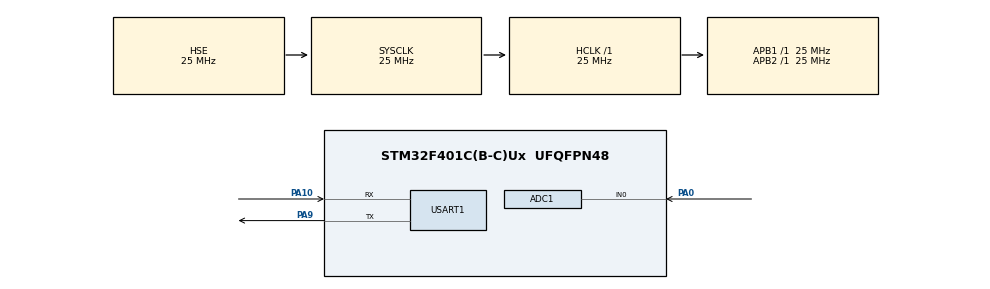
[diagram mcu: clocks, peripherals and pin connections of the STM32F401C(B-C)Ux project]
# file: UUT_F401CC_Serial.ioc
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Mcu.Family=STM32F4
Dma.ADC1.0.Instance=DMA2_Stream0
RCC.CortexFreq_Value=25000000
ADC1.Rank-0\#ChannelRegularConversion=1
PA10.Mode=Asynchronous
ADC1.ContinuousConvMode=ENABLE
PH1\ -\ OSC_OUT.Mode=HSE-External-Oscillator
RCC.SYSCLKSource=RCC_SYSCLKSOURCE_HSE
ProjectManager.StackSize=0x400
PA0-WKUP.Signal=ADCx_IN0
PA13.Signal=SYS_JTMS-SWDIO
NVIC.ADC_IRQn=true\:0\:0\:false\:false\:true\:true\:true
Dma.ADC1.0.PeriphDataAlignment=DMA_PDATAALIGN_WORD
PA9.Mode=Asynchronous
PH0\ -\ OSC_IN.Mode=HSE-External-Oscillator
PH0\ -\ OSC_IN.Signal=RCC_OSC_IN
ProjectManager.TargetToolchain=STM32CubeIDE
Dma.ADC1.0.Mode=DMA_CIRCULAR
RCC.HCLKFreq_Value=25000000
Dma.ADC1.0.Priority=DMA_PRIORITY_LOW
RCC.APB2TimFreq_Value=25000000
PA9.Signal=USART1_TX
Dma.ADC1.0.Direction=DMA_PERIPH_TO_MEMORY
NVIC.DMA2_Stream0_IRQn=true\:0\:0\:false\:false\:true\:false\:true
RCC.LSE_VALUE=32768
Dma.ADC1.0.MemDataAlignment=DMA_MDATAALIGN_WORD
RCC.AHBFreq_Value=25000000
ADC1.Channel-0\#ChannelRegularConversion=ADC_CHANNEL_0
RCC.HSE_VALUE=25000000
PH1\ -\ OSC_OUT.Signal=RCC_OSC_OUT
board=custom
RCC.VCOOutputFreq_Value=192000000
RCC.APB2Freq_Value=25000000
PA14.Mode=Serial_Wire
Dma.ADC1.0.PeriphInc=DMA_PINC_DISABLE
SH.ADCx_IN0.0=ADC1_IN0,IN0
PA13.Mode=Serial_Wire
Mcu.Name=STM32F401C(B-C)Ux
ADC1.SamplingTime-0\#ChannelRegularConversion=ADC_SAMPLETIME_3CYCLES
RCC.SYSCLKFreq_VALUE=25000000
Mcu.Package=UFQFPN48
ADC1.master=1
USART1.VirtualMode=VM_ASYNC
PA10.Signal=USART1_RX
PA14.Signal=SYS_JTCK-SWCLK
Dma.ADC1.0.MemInc=DMA_MINC_ENABLE
ProjectManager.HeapSize=0x200
RCC.HSI_VALUE=16000000
NVIC.PriorityGroup=NVIC_PRIORITYGROUP_4
ADC1.NbrOfConversionFlag=1
RCC.APB1TimFreq_Value=25000000
Dma.ADC1.0.FIFOMode=DMA_FIFOMODE_DISABLE
NVIC.USART1_IRQn=true\:0\:0\:false\:false\:true\:true\:true
RCC.APB1Freq_Value=25000000
Dma.Request0=ADC1

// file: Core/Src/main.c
/* USER CODE BEGIN Header */
/**
  ******************************************************************************
  * @file           : main.c
  * @brief          : Main program body
  ******************************************************************************
  * @attention
  *
  * <h2><center>&copy; Copyright (c) 2021 STMicroelectronics.
  * All rights reserved.</center></h2>
  *
  * This software component is licensed by ST under BSD 3-Clause license,
  * the "License"; You may not use this file except in compliance with the
  * License. You may obtain a copy of the License at:
  *                        opensource.org/licenses/BSD-3-Clause
  *
  ******************************************************************************
  */
/* USER CODE END Header */
#include "main.h"

ADC_HandleTypeDef hadc1;
DMA_HandleTypeDef hdma_adc1;

UART_HandleTypeDef huart1;

void SystemClock_Config(void);
static void MX_GPIO_Init(void);
static void MX_DMA_Init(void);
static void MX_ADC1_Init(void);
static void MX_USART1_UART_Init(void);

/* USER CODE BEGIN 0 */
uint8_t UART1_rxIndex = 0;
uint8_t UART1_rxAvailable = 0;
uint8_t UART1_rxData = 0;
uint8_t UART1_rxBuffer[250] = {0};

/* USER CODE END 0 */

int main(void)
{

  /* MCU Configuration--------------------------------------------------------*/

  /* Reset of all peripherals, Initializes the Flash interface and the Systick. */
  HAL_Init();

  /* Configure the system clock */
  SystemClock_Config();

  /* Initialize all configured peripherals */
  MX_GPIO_Init();
  MX_DMA_Init();
  MX_ADC1_Init();
  MX_USART1_UART_Init();
  /* USER CODE BEGIN 2 */
  HAL_UART_Receive_IT(&huart1, &UART1_rxData, 1);

  HAL_UART_Transmit(&huart1,(uint8_t*)"Serial Port Test\r\n",18,1000);
  HAL_UART_Transmit(&huart1,(uint8_t*)"Type any key in terminal\r\n",26,1000);
  /* USER CODE END 2 */

  /* Infinite loop */
  while (1)
  {

    /* USER CODE BEGIN 3 */
	if (UART1_rxAvailable){
	    // Clean Buffer
	    char *_token, *_buffer;
	    _buffer = _token = strtok(UART1_rxBuffer, "FI#");
	    //while(_token != NULL) {
	    //  _buffer = token;
	    //  _token = strtok(NULL, UB_LOCK_BYTES);
	    //}
	    for (;(_token = strtok(NULL, "FI#")) != NULL; _buffer = _token);

	    // Process Buffer
	    char *_item = strtok(_buffer, "=");
	    uint8_t _action = atoi(_item);
	    _item = strtok (NULL, ";");
	    uint16_t _param_a = atoi(_item);
	    _item = strtok (NULL, ";");
	    uint16_t _param_b = atoi(_item);

	    //FI_SERIAL(_action, _param_a, _param_b);

	    char buffer[100];

      HAL_UART_Transmit(&huart1,(uint8_t*)"Receive:",8,500);
      sprintf(buffer, "%d", _action);
      HAL_UART_Transmit(&huart1, (uint8_t *)buffer, strlen(buffer), 1000);
      sprintf(buffer, "%d", _param_a);
      HAL_UART_Transmit(&huart1, (uint8_t *)buffer, strlen(buffer), 1000);
      sprintf(buffer, "%d", _param_b);
      HAL_UART_Transmit(&huart1, (uint8_t *)buffer, strlen(buffer), 1000);
      HAL_UART_Transmit(&huart1,(uint8_t*)"\r\n",2,1000);
      UART1_rxAvailable = 0;
	}

  }
  /* USER CODE END 3 */
}

void SystemClock_Config(void)
{
  RCC_OscInitTypeDef RCC_OscInitStruct = {0};
  RCC_ClkInitTypeDef RCC_ClkInitStruct = {0};

  /** Configure the main internal regulator output voltage
  */
  __HAL_RCC_PWR_CLK_ENABLE();
  __HAL_PWR_VOLTAGESCALING_CONFIG(PWR_REGULATOR_VOLTAGE_SCALE2);
  /** Initializes the RCC Oscillators according to the specified parameters
  * in the RCC_OscInitTypeDef structure.
  */
  RCC_OscInitStruct.OscillatorType = RCC_OSCILLATORTYPE_HSE;
  RCC_OscInitStruct.HSEState = RCC_HSE_ON;
  RCC_OscInitStruct.PLL.PLLState = RCC_PLL_NONE;
  if (HAL_RCC_OscConfig(&RCC_OscInitStruct) != HAL_OK)
  {
    Error_Handler();
  }
  /** Initializes the CPU, AHB and APB buses clocks
  */
  RCC_ClkInitStruct.ClockType = RCC_CLOCKTYPE_HCLK|RCC_CLOCKTYPE_SYSCLK
                              |RCC_CLOCKTYPE_PCLK1|RCC_CLOCKTYPE_PCLK2;
  RCC_ClkInitStruct.SYSCLKSource = RCC_SYSCLKSOURCE_HSE;
  RCC_ClkInitStruct.AHBCLKDivider = RCC_SYSCLK_DIV1;
  RCC_ClkInitStruct.APB1CLKDivider = RCC_HCLK_DIV1;
  RCC_ClkInitStruct.APB2CLKDivider = RCC_HCLK_DIV1;

  if (HAL_RCC_ClockConfig(&RCC_ClkInitStruct, FLASH_LATENCY_0) != HAL_OK)
  {
    Error_Handler();
  }
}

static void MX_ADC1_Init(void)
{

  ADC_ChannelConfTypeDef sConfig = {0};

  /** Configure the global features of the ADC (Clock, Resolution, Data Alignment and number of conversion)
  */
  hadc1.Instance = ADC1;
  hadc1.Init.ClockPrescaler = ADC_CLOCK_SYNC_PCLK_DIV2;
  hadc1.Init.Resolution = ADC_RESOLUTION_12B;
  hadc1.Init.ScanConvMode = DISABLE;
  hadc1.Init.ContinuousConvMode = ENABLE;
  hadc1.Init.DiscontinuousConvMode = DISABLE;
  hadc1.Init.ExternalTrigConvEdge = ADC_EXTERNALTRIGCONVEDGE_NONE;
  hadc1.Init.ExternalTrigConv = ADC_SOFTWARE_START;
  hadc1.Init.DataAlign = ADC_DATAALIGN_RIGHT;
  hadc1.Init.NbrOfConversion = 1;
  hadc1.Init.DMAContinuousRequests = DISABLE;
  hadc1.Init.EOCSelection = ADC_EOC_SINGLE_CONV;
  if (HAL_ADC_Init(&hadc1) != HAL_OK)
  {
    Error_Handler();
  }
  /** Configure for the selected ADC regular channel its corresponding rank in the sequencer and its sample time.
  */
  sConfig.Channel = ADC_CHANNEL_0;
  sConfig.Rank = 1;
  sConfig.SamplingTime = ADC_SAMPLETIME_3CYCLES;
  if (HAL_ADC_ConfigChannel(&hadc1, &sConfig) != HAL_OK)
  {
    Error_Handler();
  }

}

static void MX_USART1_UART_Init(void)
{

  huart1.Instance = USART1;
  huart1.Init.BaudRate = 115200;
  huart1.Init.WordLength = UART_WORDLENGTH_8B;
  huart1.Init.StopBits = UART_STOPBITS_1;
  huart1.Init.Parity = UART_PARITY_NONE;
  huart1.Init.Mode = UART_MODE_TX_RX;
  huart1.Init.HwFlowCtl = UART_HWCONTROL_NONE;
  huart1.Init.OverSampling = UART_OVERSAMPLING_16;
  if (HAL_UART_Init(&huart1) != HAL_OK)
  {
    Error_Handler();
  }

}

static void MX_DMA_Init(void)
{

  /* DMA controller clock enable */
  __HAL_RCC_DMA2_CLK_ENABLE();

  /* DMA interrupt init */
  /* DMA2_Stream0_IRQn interrupt configuration */
  HAL_NVIC_SetPriority(DMA2_Stream0_IRQn, 0, 0);
  HAL_NVIC_EnableIRQ(DMA2_Stream0_IRQn);

}

static void MX_GPIO_Init(void)
{

  /* GPIO Ports Clock Enable */
  __HAL_RCC_GPIOH_CLK_ENABLE();
  __HAL_RCC_GPIOA_CLK_ENABLE();

}

/* USER CODE BEGIN 4 */
void HAL_UART_RxCpltCallback(UART_HandleTypeDef *huart)
{
    if(huart->Instance == USART1){

        if(UART1_rxIndex == 0){
            memset(&UART1_rxBuffer, 0, sizeof(UART1_rxBuffer));
        }

        char _char = UART1_rxData;
        UART1_rxBuffer[UART1_rxIndex++] = _char;

        if(_char == '\n'){
            UART1_rxBuffer[UART1_rxIndex] = '\0';
            UART1_rxIndex = 0;
            if(strstr(UART1_rxBuffer, "FI#") != NULL){
            	// Serial.print("[+++]");
            	UART1_rxAvailable = 1;
            }
        }

        // Receive next character (1 byte)
        HAL_UART_Receive_IT(&huart1, &UART1_rxData, 1);
    }
}
/* USER CODE END 4 */

void Error_Handler(void)
{
  __disable_irq();
  while (1)
  {
  }
}

/************************ (C) COPYRIGHT STMicroelectronics *****END OF FILE****/
